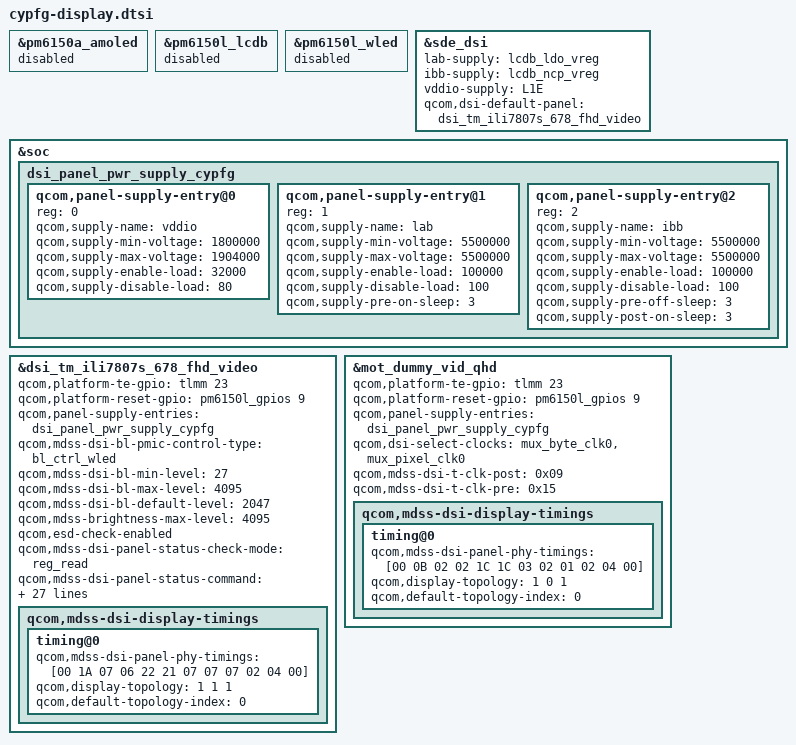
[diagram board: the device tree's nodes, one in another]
#include "dsi-panel-mot-dummy-qhd-video.dtsi"
#include "dsi-panel-mot-tianma-ili7807s-678-1080x2460-video.dtsi"


&pm6150a_amoled {
	status = "disabled";
};

&pm6150l_lcdb {
	status = "disabled";
};

&pm6150l_wled {
	status = "disabled";
};

&sde_dsi {
	lab-supply = <&lcdb_ldo_vreg>;
	ibb-supply = <&lcdb_ncp_vreg>;
	vddio-supply = <&L1E>;

	qcom,dsi-default-panel = <&dsi_tm_ili7807s_678_fhd_video>;
};
&soc {
	dsi_panel_pwr_supply_cypfg: dsi_panel_pwr_supply_cypfg{
		#address-cells = <1>;
		#size-cells = <0>;

		qcom,panel-supply-entry@0 {
			reg = <0>;
			qcom,supply-name = "vddio";
			qcom,supply-min-voltage = <1800000>;
			qcom,supply-max-voltage = <1904000>;
			qcom,supply-enable-load = <32000>;
			qcom,supply-disable-load = <80>;
		};

		qcom,panel-supply-entry@1 {
			reg = <1>;
			qcom,supply-name = "lab";
			qcom,supply-min-voltage = <5500000>;
			qcom,supply-max-voltage = <5500000>;
			qcom,supply-enable-load = <100000>;
			qcom,supply-disable-load = <100>;
			qcom,supply-pre-on-sleep = <3>;
		};

		qcom,panel-supply-entry@2 {
			reg = <2>;
			qcom,supply-name = "ibb";
			qcom,supply-min-voltage = <5500000>;
			qcom,supply-max-voltage = <5500000>;
			qcom,supply-enable-load = <100000>;
			qcom,supply-disable-load = <100>;
			qcom,supply-pre-off-sleep = <3>;
			qcom,supply-post-on-sleep = <3>;
		};
	};
};


&dsi_tm_ili7807s_678_fhd_video {
	qcom,platform-te-gpio = <&tlmm 23 0>;
	qcom,platform-reset-gpio = <&pm6150l_gpios 9 0>;

	qcom,panel-supply-entries = <&dsi_panel_pwr_supply_cypfg>;

	qcom,mdss-dsi-bl-pmic-control-type = "bl_ctrl_wled";

	qcom,mdss-dsi-bl-min-level = <27>;
	qcom,mdss-dsi-bl-max-level = <4095>;
	qcom,mdss-dsi-bl-default-level = <2047>;
	qcom,mdss-brightness-max-level = <4095>;

	qcom,esd-check-enabled;
	qcom,mdss-dsi-panel-status-check-mode = "reg_read";
	qcom,mdss-dsi-panel-status-command = [06 01 00 01 00 00 01 0a];
	qcom,mdss-dsi-panel-status-command-state = "dsi_lp_mode";
	qcom,mdss-dsi-panel-status-value = <0x9c>;
	qcom,mdss-dsi-panel-on-check-value = <0x9c>;
	qcom,mdss-dsi-panel-status-read-length = <1>;
	qcom,mdss-dsi-no-panel-on-read-support;
	qcom,mdss-dsi-panel-supplier = "tm";
	qcom,platform-reset-gpio-always-on;

	qcom,tp_state_check_enable;

	qcom,mdss-dsi-pan-enable-dynamic-fps;
	qcom,mdss-dsi-pan-fps-update = "dfps_immediate_porch_mode_vfp";
	qcom,dsi-supported-dfps-list = <60 120>;

	//qcom,mdss-dsi-panel-hdr-enabled;
	//qcom,mdss-dsi-panel-hdr-color-primaries = <15115 15895 32830
	//			16770 15010 32385 7770 1830>;
	//qcom,mdss-dsi-panel-peak-brightness = <4500000>;
	//qcom,mdss-dsi-panel-blackness-level = <3000>;

	qcom,mdss-dsi-hbm-on-command = [39 01 00 00 00 00 03 51 03 FF];
	qcom,mdss-dsi-hbm-on-command-state =  "dsi_hs_mode";
	qcom,mdss-dsi-hbm-off-command = [39 01 00 00 00 00 03 51 03 32];
	qcom,mdss-dsi-hbm-off-command-state = "dsi_hs_mode";
	qcom,mdss-dsi-hbm-type = "lcd-dcs-wled";

	qcom,dsi-select-clocks = "mux_byte_clk0", "mux_pixel_clk0";
	qcom,mdss-dsi-t-clk-post = <0x0C>;
	qcom,mdss-dsi-t-clk-pre = <0x30>;
	qcom,mdss-dsi-display-timings {
		timing@0 {
			qcom,mdss-dsi-panel-phy-timings = [00 1A 07 06 22 21 07
				07 07 02 04 00];
			qcom,display-topology = <1 1 1>;
			qcom,default-topology-index = <0>;
		};
	};
};



&mot_dummy_vid_qhd {
	qcom,platform-te-gpio = <&tlmm 23 0>;
	qcom,platform-reset-gpio = <&pm6150l_gpios 9 0>;

	qcom,panel-supply-entries = <&dsi_panel_pwr_supply_cypfg>;

	qcom,dsi-select-clocks = "mux_byte_clk0", "mux_pixel_clk0";
	qcom,mdss-dsi-t-clk-post = <0x09>;
	qcom,mdss-dsi-t-clk-pre = <0x15>;
	qcom,mdss-dsi-display-timings {
		timing@0 {
			qcom,mdss-dsi-panel-phy-timings = [00 0B 02 02 1C 1C 03
							02 01 02 04 00];
			qcom,display-topology = <1 0 1>;
			qcom,default-topology-index = <0>;
		};
	};
};
